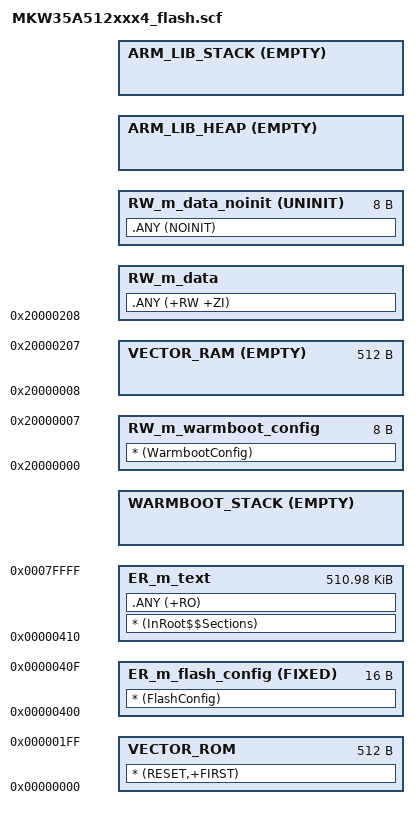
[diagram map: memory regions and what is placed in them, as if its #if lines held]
#! armcc -E
/*
** ###################################################################
**     Processors:          MKW35A512VFP4
**                          MKW35A512VFT4
**
**     Compiler:            Keil ARM C/C++ Compiler
**     Reference manual:    MKW36A512RM Rev. 7, 07/2019
**     Version:             rev. 1.4, 2019-01-25
**     Build:               b190125
**
**     Abstract:
**         Linker file for the Keil ARM C/C++ Compiler
**
**     Copyright 2016 Freescale Semiconductor, Inc.
**     Copyright 2016-2019 NXP
**     All rights reserved.
**
**     SPDX-License-Identifier: BSD-3-Clause
**
**     http:                 www.nxp.com
**     mail:                 support@nxp.com
**
** ###################################################################
*/

#if (defined(__ram_vector_table__))
  #define __ram_vector_table_size__    0x00000200
#else
  #define __ram_vector_table_size__    0x00000000
#endif

#if (defined(__warmboot_stack_addr__))
  #define warmboot_stack_addr          __warmboot_stack_addr__
#else
  #define warmboot_stack_addr          0x1FFFC000
#endif

#if (defined(__warmboot_stack_size__))
  #define warmboot_stack_size          __warmboot_stack_size__
#else
  #define warmboot_stack_size          0x00000400
#endif

#define m_interrupts_start             0x00000000
#define m_interrupts_size              0x00000200

#define m_flash_config_start           0x00000400
#define m_flash_config_size            0x00000010

#define m_text_start                   0x00000410
#define m_text_size                    0x0007FBF0

#define m_warmboot_stack_start         warmboot_stack_addr
#define m_warmboot_stack_size          warmboot_stack_size

#define m_warmboot_config_start        0x20000000
#define m_warmboot_config_size         0x00000008

#define m_interrupts_ram_start         0x20000008
#define m_interrupts_ram_size          __ram_vector_table_size__

#define m_data_start                   (m_interrupts_ram_start + m_interrupts_ram_size)
#define m_data_size                    (0x0000BFF8 - m_interrupts_ram_size)

#define m_data_noinit_size             0x00000008

/* Sizes */
#if (defined(__stack_size__))
  #define Stack_Size                   __stack_size__
#else
  #define Stack_Size                   0x0400
#endif

#if (defined(__heap_size__))
  #define Heap_Size                    __heap_size__
#else
  #define Heap_Size                    0x0400
#endif

LR_m_text m_interrupts_start m_text_start+m_text_size-m_interrupts_start { ; load region size_region
  VECTOR_ROM m_interrupts_start m_interrupts_size { ; load address = execution address
    * (RESET,+FIRST)
  }
  ER_m_flash_config m_flash_config_start FIXED m_flash_config_size { ; load address = execution address
    * (FlashConfig)
  }
  ER_m_text m_text_start m_text_size { ; load address = execution address
    * (InRoot$$Sections)
    .ANY (+RO)
  }

  WARMBOOT_STACK m_warmboot_stack_start+m_warmboot_stack_size EMPTY -m_warmboot_stack_size { ; Warmboot Stack
  }
  RW_m_warmboot_config m_warmboot_config_start m_warmboot_config_size {
    * (WarmbootConfig)
  }
#if (defined(__ram_vector_table__))
  VECTOR_RAM m_interrupts_ram_start EMPTY m_interrupts_ram_size {
  }
#else
  VECTOR_RAM m_interrupts_start EMPTY 0 {
  }
#endif
  RW_m_data m_data_start m_data_size-Stack_Size-Heap_Size { ; RW data
    .ANY (+RW +ZI)
  }
  RW_m_data_noinit +0 UNINIT m_data_noinit_size { ; NOINIT data
    .ANY (NOINIT)
  }
  ARM_LIB_HEAP +0 EMPTY Heap_Size {    ; Heap region growing up
  }
  ARM_LIB_STACK m_data_start+m_data_size EMPTY -Stack_Size { ; Stack region growing down
  }
}

